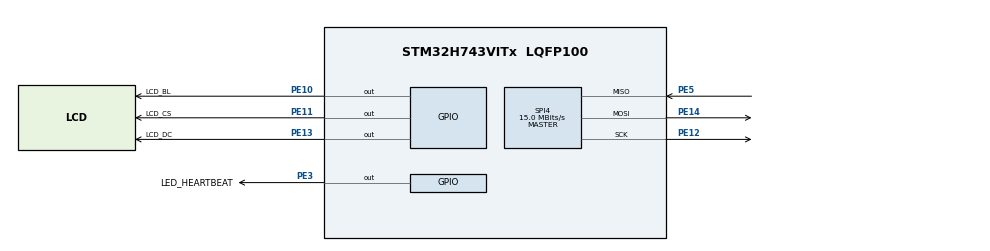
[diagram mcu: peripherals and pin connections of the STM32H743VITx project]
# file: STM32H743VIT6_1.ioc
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CORTEX_M7.default_mode_Activation=1
Mcu.Family=STM32H7
Mcu.Name=STM32H743VITx
Mcu.Package=LQFP100
NVIC.PriorityGroup=NVIC_PRIORITYGROUP_4
PC14-OSC32_IN\ (OSC32_IN).Mode=LSE-External-Oscillator
PC14-OSC32_IN\ (OSC32_IN).Signal=RCC_OSC32_IN
PC15-OSC32_OUT\ (OSC32_OUT).Mode=LSE-External-Oscillator
PC15-OSC32_OUT\ (OSC32_OUT).Signal=RCC_OSC32_OUT
PE10.GPIO_Label=LCD_BL
PE10.PinState=GPIO_PIN_RESET
PE10.Signal=GPIO_Output
PE11.GPIO_Label=LCD_CS
PE11.GPIO_Speed=GPIO_SPEED_FREQ_VERY_HIGH
PE11.Signal=GPIO_Output
PE12.Mode=Full_Duplex_Master
PE12.Signal=SPI4_SCK
PE13.GPIO_Label=LCD_DC
PE13.GPIO_Speed=GPIO_SPEED_FREQ_VERY_HIGH
PE13.Signal=GPIO_Output
PE14.Mode=Full_Duplex_Master
PE14.Signal=SPI4_MOSI
PE3.GPIO_Label=LED_HEARTBEAT
PE3.Signal=GPIO_Output
PE5.Mode=Full_Duplex_Master
PE5.Signal=SPI4_MISO
PH0-OSC_IN\ (PH0).Mode=HSE-External-Oscillator
PH0-OSC_IN\ (PH0).Signal=RCC_OSC_IN
PH1-OSC_OUT\ (PH1).Mode=HSE-External-Oscillator
PH1-OSC_OUT\ (PH1).Signal=RCC_OSC_OUT
ProjectManager.HeapSize=0x200
ProjectManager.StackSize=0x400
ProjectManager.TargetToolchain=STM32CubeIDE
RCC.ADCFreq_Value=129000000
RCC.APB1Freq_Value=120000000
RCC.APB2Freq_Value=60000000
RCC.APB3Freq_Value=120000000
RCC.APB4Freq_Value=120000000
RCC.CortexFreq_Value=240000000
RCC.D2PPRE2=RCC_APB2_DIV2
RCC.DIVM1=4
RCC.DIVN1=30
RCC.HCLKFreq_Value=120000000
RCC.HPRE=RCC_HCLK_DIV2
RCC.PLL2FRACN=0
RCC.PLL3FRACN=0
RCC.PLLFRACN=0
RCC.SYSCLKFreq_VALUE=240000000
RCC.SYSCLKSource=RCC_SYSCLKSOURCE_PLLCLK
RCC.USBFreq_Value=240000000
SPI4.BaudRatePrescaler=SPI_BAUDRATEPRESCALER_4
SPI4.CLKPhase=SPI_PHASE_1EDGE
SPI4.CLKPolarity=SPI_POLARITY_LOW
SPI4.CalculateBaudRate=15.0 MBits/s
SPI4.DataSize=SPI_DATASIZE_8BIT
SPI4.Direction=SPI_DIRECTION_2LINES
SPI4.Mode=SPI_MODE_MASTER
SPI4.VirtualType=VM_MASTER
VP_MEMORYMAP_VS_MEMORYMAP.Mode=CurAppReg
board=custom

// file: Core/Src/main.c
/* USER CODE BEGIN Header */
/**
  ******************************************************************************
  * @file           : main.c
  * @brief          : Main program body
  ******************************************************************************
  * @attention
  *
  * Copyright (c) 2026 STMicroelectronics.
  * All rights reserved.
  *
  * This software is licensed under terms that can be found in the LICENSE file
  * in the root directory of this software component.
  * If no LICENSE file comes with this software, it is provided AS-IS.
  *
  ******************************************************************************
  */
/* USER CODE END Header */
#include "main.h"

/* USER CODE BEGIN Includes */
#include "st7735.h"
#include "font.h"
/* USER CODE END Includes */

SPI_HandleTypeDef hspi4;

void SystemClock_Config(void);
static void MPU_Config(void);
static void MX_GPIO_Init(void);
static void MX_SPI4_Init(void);

int main(void)
{

  /* MPU Configuration--------------------------------------------------------*/
  MPU_Config();

  /* MCU Configuration--------------------------------------------------------*/

  /* Reset of all peripherals, Initializes the Flash interface and the Systick. */
  HAL_Init();

  /* Configure the system clock */
  SystemClock_Config();

  /* Initialize all configured peripherals */
  MX_GPIO_Init();
  MX_SPI4_Init();
  /* USER CODE BEGIN 2 */
  HAL_GPIO_WritePin(GPIOE, GPIO_PIN_10, GPIO_PIN_SET);

    // Если экран всё равно черный, попробуйте на секунду RESET
    // HAL_GPIO_WritePin(GPIOE, GPIO_PIN_10, GPIO_PIN_RESET);

    HAL_Delay(100); // Даем время прогреться

    ST7735_Init();
    ST7735_FillScreen(ST7735_RED);
  /* USER CODE END 2 */

  /* Infinite loop */
  /* USER CODE BEGIN WHILE */
  while (1)
  {

	    HAL_GPIO_TogglePin(GPIOE, LED_HEARTBEAT_Pin);
	    HAL_Delay(3000);
    /* USER CODE END WHILE */

  }
}

void SystemClock_Config(void)
{
  RCC_OscInitTypeDef RCC_OscInitStruct = {0};
  RCC_ClkInitTypeDef RCC_ClkInitStruct = {0};

  /** Supply configuration update enable
  */
  HAL_PWREx_ConfigSupply(PWR_LDO_SUPPLY);

  /** Configure the main internal regulator output voltage
  */
  __HAL_PWR_VOLTAGESCALING_CONFIG(PWR_REGULATOR_VOLTAGE_SCALE2);

  while(!__HAL_PWR_GET_FLAG(PWR_FLAG_VOSRDY)) {}

  /** Initializes the RCC Oscillators according to the specified parameters
  * in the RCC_OscInitTypeDef structure.
  */
  RCC_OscInitStruct.OscillatorType = RCC_OSCILLATORTYPE_HSI;
  RCC_OscInitStruct.HSIState = RCC_HSI_DIV1;
  RCC_OscInitStruct.HSICalibrationValue = RCC_HSICALIBRATION_DEFAULT;
  RCC_OscInitStruct.PLL.PLLState = RCC_PLL_ON;
  RCC_OscInitStruct.PLL.PLLSource = RCC_PLLSOURCE_HSI;
  RCC_OscInitStruct.PLL.PLLM = 4;
  RCC_OscInitStruct.PLL.PLLN = 30;
  RCC_OscInitStruct.PLL.PLLP = 2;
  RCC_OscInitStruct.PLL.PLLQ = 2;
  RCC_OscInitStruct.PLL.PLLR = 2;
  RCC_OscInitStruct.PLL.PLLRGE = RCC_PLL1VCIRANGE_3;
  RCC_OscInitStruct.PLL.PLLVCOSEL = RCC_PLL1VCOWIDE;
  RCC_OscInitStruct.PLL.PLLFRACN = 0;
  if (HAL_RCC_OscConfig(&RCC_OscInitStruct) != HAL_OK)
  {
    Error_Handler();
  }

  /** Initializes the CPU, AHB and APB buses clocks
  */
  RCC_ClkInitStruct.ClockType = RCC_CLOCKTYPE_HCLK|RCC_CLOCKTYPE_SYSCLK
                              |RCC_CLOCKTYPE_PCLK1|RCC_CLOCKTYPE_PCLK2
                              |RCC_CLOCKTYPE_D3PCLK1|RCC_CLOCKTYPE_D1PCLK1;
  RCC_ClkInitStruct.SYSCLKSource = RCC_SYSCLKSOURCE_PLLCLK;
  RCC_ClkInitStruct.SYSCLKDivider = RCC_SYSCLK_DIV1;
  RCC_ClkInitStruct.AHBCLKDivider = RCC_HCLK_DIV2;
  RCC_ClkInitStruct.APB3CLKDivider = RCC_APB3_DIV1;
  RCC_ClkInitStruct.APB1CLKDivider = RCC_APB1_DIV1;
  RCC_ClkInitStruct.APB2CLKDivider = RCC_APB2_DIV2;
  RCC_ClkInitStruct.APB4CLKDivider = RCC_APB4_DIV1;

  if (HAL_RCC_ClockConfig(&RCC_ClkInitStruct, FLASH_LATENCY_2) != HAL_OK)
  {
    Error_Handler();
  }
}

static void MX_SPI4_Init(void)
{

  /* SPI4 parameter configuration*/
  hspi4.Instance = SPI4;
  hspi4.Init.Mode = SPI_MODE_MASTER;
  hspi4.Init.Direction = SPI_DIRECTION_2LINES;
  hspi4.Init.DataSize = SPI_DATASIZE_8BIT;
  hspi4.Init.CLKPolarity = SPI_POLARITY_LOW;
  hspi4.Init.CLKPhase = SPI_PHASE_1EDGE;
  hspi4.Init.NSS = SPI_NSS_SOFT;
  hspi4.Init.BaudRatePrescaler = SPI_BAUDRATEPRESCALER_4;
  hspi4.Init.FirstBit = SPI_FIRSTBIT_MSB;
  hspi4.Init.TIMode = SPI_TIMODE_DISABLE;
  hspi4.Init.CRCCalculation = SPI_CRCCALCULATION_DISABLE;
  hspi4.Init.CRCPolynomial = 0x0;
  hspi4.Init.NSSPMode = SPI_NSS_PULSE_ENABLE;
  hspi4.Init.NSSPolarity = SPI_NSS_POLARITY_LOW;
  hspi4.Init.FifoThreshold = SPI_FIFO_THRESHOLD_01DATA;
  hspi4.Init.TxCRCInitializationPattern = SPI_CRC_INITIALIZATION_ALL_ZERO_PATTERN;
  hspi4.Init.RxCRCInitializationPattern = SPI_CRC_INITIALIZATION_ALL_ZERO_PATTERN;
  hspi4.Init.MasterSSIdleness = SPI_MASTER_SS_IDLENESS_00CYCLE;
  hspi4.Init.MasterInterDataIdleness = SPI_MASTER_INTERDATA_IDLENESS_00CYCLE;
  hspi4.Init.MasterReceiverAutoSusp = SPI_MASTER_RX_AUTOSUSP_DISABLE;
  hspi4.Init.MasterKeepIOState = SPI_MASTER_KEEP_IO_STATE_DISABLE;
  hspi4.Init.IOSwap = SPI_IO_SWAP_DISABLE;
  if (HAL_SPI_Init(&hspi4) != HAL_OK)
  {
    Error_Handler();
  }

}

static void MX_GPIO_Init(void)
{
  GPIO_InitTypeDef GPIO_InitStruct = {0};

  /* GPIO Ports Clock Enable */
  __HAL_RCC_GPIOE_CLK_ENABLE();
  __HAL_RCC_GPIOC_CLK_ENABLE();
  __HAL_RCC_GPIOH_CLK_ENABLE();

  /*Configure GPIO pin Output Level */
  HAL_GPIO_WritePin(GPIOE, LED_HEARTBEAT_Pin|LCD_BL_Pin|LCD_CS_Pin|LCD_DC_Pin, GPIO_PIN_RESET);

  /*Configure GPIO pins : LED_HEARTBEAT_Pin LCD_BL_Pin */
  GPIO_InitStruct.Pin = LED_HEARTBEAT_Pin|LCD_BL_Pin;
  GPIO_InitStruct.Mode = GPIO_MODE_OUTPUT_PP;
  GPIO_InitStruct.Pull = GPIO_NOPULL;
  GPIO_InitStruct.Speed = GPIO_SPEED_FREQ_LOW;
  HAL_GPIO_Init(GPIOE, &GPIO_InitStruct);

  /*Configure GPIO pins : LCD_CS_Pin LCD_DC_Pin */
  GPIO_InitStruct.Pin = LCD_CS_Pin|LCD_DC_Pin;
  GPIO_InitStruct.Mode = GPIO_MODE_OUTPUT_PP;
  GPIO_InitStruct.Pull = GPIO_NOPULL;
  GPIO_InitStruct.Speed = GPIO_SPEED_FREQ_VERY_HIGH;
  HAL_GPIO_Init(GPIOE, &GPIO_InitStruct);

}

 /* MPU Configuration */

void MPU_Config(void)
{
  MPU_Region_InitTypeDef MPU_InitStruct = {0};

  /* Disables the MPU */
  HAL_MPU_Disable();

  /** Initializes and configures the Region and the memory to be protected
  */
  MPU_InitStruct.Enable = MPU_REGION_ENABLE;
  MPU_InitStruct.Number = MPU_REGION_NUMBER0;
  MPU_InitStruct.BaseAddress = 0x0;
  MPU_InitStruct.Size = MPU_REGION_SIZE_4GB;
  MPU_InitStruct.SubRegionDisable = 0x87;
  MPU_InitStruct.TypeExtField = MPU_TEX_LEVEL0;
  MPU_InitStruct.AccessPermission = MPU_REGION_NO_ACCESS;
  MPU_InitStruct.DisableExec = MPU_INSTRUCTION_ACCESS_DISABLE;
  MPU_InitStruct.IsShareable = MPU_ACCESS_SHAREABLE;
  MPU_InitStruct.IsCacheable = MPU_ACCESS_NOT_CACHEABLE;
  MPU_InitStruct.IsBufferable = MPU_ACCESS_NOT_BUFFERABLE;

  HAL_MPU_ConfigRegion(&MPU_InitStruct);
  /* Enables the MPU */
  HAL_MPU_Enable(MPU_PRIVILEGED_DEFAULT);

}

void Error_Handler(void)
{
  __disable_irq();
  while (1)
  {
  }
}
